# ESP32-S31 register map
Vendor: ESPRESSIF SYSTEMS (SHANGHAI) CO., LTD.; Series: ESP32 S-Series; File version: 1
CPU: RV32IMAFC r0p0, little endian, no MPU, FPU, 0 interrupt priority bits
Address unit: 32 bits
Registers are 32-bit, read-write, reset 0x0 unless marked. A register's access mark holds for its fields unless they carry their own. Offsets are from the block's base; [hi:lo] are bit positions; {n}, {i} and the like mark numbered series.

## TRACE0 — TRACE0 Peripheral
Base 0x2D000000
Same registers: TRACE1 0x2D001000
0x00 MEM_START_ADDR
  [31:0] MEM_START_ADDR — The start address of trace memory
0x04 MEM_END_ADDR reset 0xFFFFFFFF
  [31:0] MEM_END_ADDR — The end address of trace memory
0x08 MEM_CURRENT_ADDR ro
  [31:0] MEM_CURRENT_ADDR — current_mem_addr,indicate that next writing addr
0x0C MEM_ADDR_UPDATE wo
  [0] MEM_CURRENT_ADDR_UPDATE — when set, the will \hyperref[fielddesc:TRACEMEMCURRENTADDR]{TRACE_MEM_CURRENT_ADDR} update to \hyperref[fielddesc:TRACEMEMSTARTADDR]{TRACE_MEM_START_ADDR}.
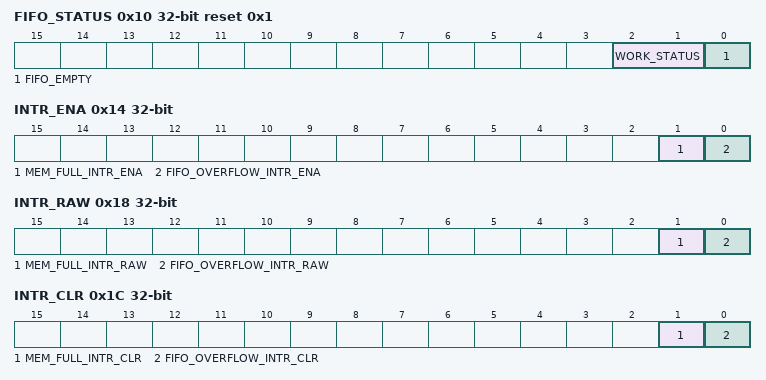
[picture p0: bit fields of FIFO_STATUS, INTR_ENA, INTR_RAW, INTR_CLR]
0x10 FIFO_STATUS ro reset 0x1
  [2:1] WORK_STATUS — Represent trace work status: \\0: idle state \\1: working state\\ 2: wait state due to hart halted or havereset \\3: lost state
  [0] FIFO_EMPTY — Represent whether the fifo is empty. \\1: empty \\0: not empty
0x14 INTR_ENA — interrupt enable register
  [1] MEM_FULL_INTR_ENA — Set 1 enable mem_full interrupt
  [0] FIFO_OVERFLOW_INTR_ENA — Set 1 enable fifo_overflow interrupt
0x18 INTR_RAW ro — interrupt status register
  [1] MEM_FULL_INTR_RAW — mem_full interrupt status
  [0] FIFO_OVERFLOW_INTR_RAW — fifo_overflow interrupt status
0x1C INTR_CLR wo — interrupt clear register
  [1] MEM_FULL_INTR_CLR — Set 1 to clear mem full interrupt
  [0] FIFO_OVERFLOW_INTR_CLR — Set 1 to clear fifo overflow interrupt
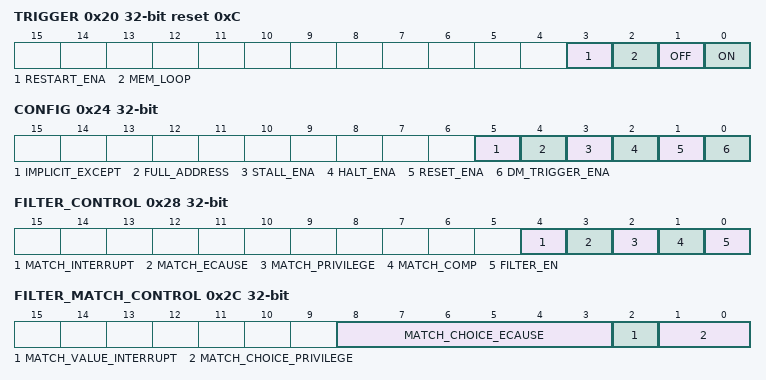
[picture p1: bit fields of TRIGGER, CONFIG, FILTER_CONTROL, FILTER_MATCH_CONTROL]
0x20 TRIGGER access per field reset 0xC
  [3] RESTART_ENA rw — Configure whether or not enable auto-restart.\\1: enable\\0: disable\\
  [2] MEM_LOOP rw — Configure memory loop mode. \\1: trace will loop wrtie trace_mem. \\0: when mem_current_addr at mem_end_addr, it will stop at the mem_end_addr\\
  [1] OFF wo — Configure whether or not stop trace.\\1: stop trace \\0: invalid\\
  [0] ON wo — Configure whether or not start trace.\\1: start trace \\0: invalid\\
0x24 CONFIG — trace configuration register
  [5] IMPLICIT_EXCEPT — Configure whether or not enabel implicit exception mode. When enabled,, do not sent exception address, only exception cause in exception packets.\\1: enabled\\0: disabled\\
  [4] FULL_ADDRESS — Configure whether or not enable full-address mode.\\1: full address mode.\\0: delta address mode\\
  [3] STALL_ENA — Configure whether or not enable stall cpu. When enabled, when the fifo almost full, the cpu will be stalled until the packets is able to write to fifo.\\1: enabled.\\0: disabled\\
  [2] HALT_ENA — Configure whether or not enable trace cpu is halted, when enabeld, if the cpu halted, the encoder will output a packet to report the address of the last instruction, and upon halted deassertion, the encoder start again.When disabled, encoder will not report the last address before halted and first address after halted, cpu halted information will not be tracked. \\1: enabeld\\0: disabled\\
  [1] RESET_ENA — Configure whether or not enable trace cpu haverest, when enabeld, if cpu have reset, the encoder will output a packet to report the address of the last instruction, and upon reset deassertion, the encoder start again.\\1: enabeld\\0: disabled\\
  [0] DM_TRIGGER_ENA — Configure whether or not enable cpu trigger action.\\1: enable\\0:disable\\
0x28 FILTER_CONTROL
  [4] MATCH_INTERRUPT — when set, start matching from a trap with the interrupt level codes specified by \hyperref[fielddesc:TRACEMATCHVALUEINTERRUPT]{TRACE_MATCH_VALUE_INTERRUPT}, and stop matching upon return from the 1st matching trap.
  [3] MATCH_ECAUSE — when set, start matching from exception cause codes specified by \hyperref[fielddesc:TRACEMATCHCHOICEECAUSE]{TRACE_MATCH_CHOICE_ECAUSE}, and stop matching upon return from the 1st matching exception.
  [2] MATCH_PRIVILEGE — when set, match privilege levels specified by \hyperref[fielddesc:TRACEMATCHCHOICEPRIVILEGE]{TRACE_MATCH_CHOICE_PRIVILEGE}.
  [1] MATCH_COMP — when set, the comparator must be high in order for the filter to match
  [0] FILTER_EN — Configure whether or not enable filter unit. \\1: enable filter.\\ 0: always match
0x2C FILTER_MATCH_CONTROL
  [8:3] MATCH_CHOICE_ECAUSE — specified which ecause matched.
  [2] MATCH_VALUE_INTERRUPT — Select which match which itype when \hyperref[fielddesc:TRACEMATCHINTERRUPT]{TRACE_MATCH_INTERRUP} is set. \\1: match itype of 2. \\0: match itype of 1.
  [1:0] MATCH_CHOICE_PRIVILEGE — Select match which privilege level when \hyperref[fielddesc:TRACEMATCHPRIVILEGE]{TRACE_MATCH_PRIVILEGE} is set. \\2'b11: machine mode. \\2'b0: user mode. \\2'b01: supervisor mode
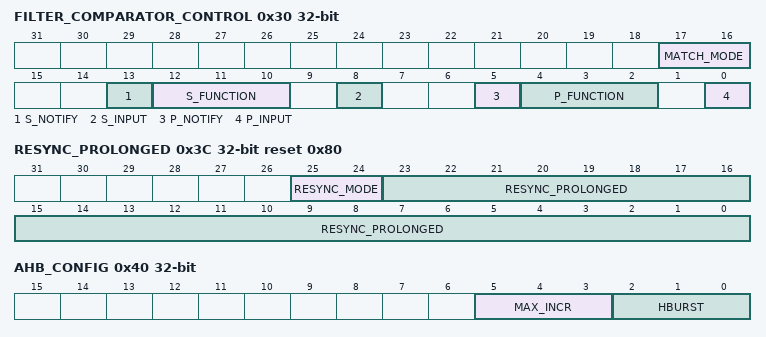
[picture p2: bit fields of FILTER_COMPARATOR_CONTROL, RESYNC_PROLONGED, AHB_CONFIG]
0x30 FILTER_COMPARATOR_CONTROL — filter comparator match control register
  [17:16] MATCH_MODE — 0: only primary matches, \\1: primary and secondary comparator both matches(P\&\&S),\\ 2:either primary or secondary comparator matches !(P\&\&S), \\3: set when primary matches and continue to match until after secondary comparator matches
  [13] S_NOTIFY — Generate a trace packet explicitly reporting the address that cause the secondary match
  [12:10] S_FUNCTION — Select the secondary comparator function. \\0: equal, \\1: not equal, \\2: less than, \\3: less than or equal, \\4: greater than, \\5: greater than or equal, \\other: always match
  [8] S_INPUT — Determines which input to compare against the secondary comparator, \\0: iaddr, \\1: tval.
  [5] P_NOTIFY — Generate a trace packet explicitly reporting the address that cause the primary match
  [4:2] P_FUNCTION — Select the primary comparator function. \\0: equal, \\1: not equal, \\2: less than, \\3: less than or equal, \\4: greater than, \\5: greater than or equal, \\other: always match
  [0] P_INPUT — Determines which input to compare against the primary comparator, \\0: iaddr, \\1: tval.
0x34 FILTER_P_COMPARATOR_MATCH — primary comparator match value
  [31:0] P_MATCH
0x38 FILTER_S_COMPARATOR_MATCH — secondary comparator match value
  [31:0] S_MATCH
0x3C RESYNC_PROLONGED reset 0x80 — resync configuration register
  [25:24] RESYNC_MODE — resyc mode sel: \\0: off, \\2: package num count \\3: cycle count
  [23:0] RESYNC_PROLONGED — count number, when count to this value, send a sync package
0x40 AHB_CONFIG
  [5:3] MAX_INCR — set max continuous access for incr mode
  [2:0] HBURST — set hburst
0x44 CLOCK_GATE reset 0x1 — Clock gate control register
  [0] CLK_EN — The bit is used to enable clock gate when access all registers in this module.
0x3FC DATE reset 0x2308290 — Version control register
  [27:0] DATE — version control register. Note that this default value stored is the latest date when the hardware logic was updated.
